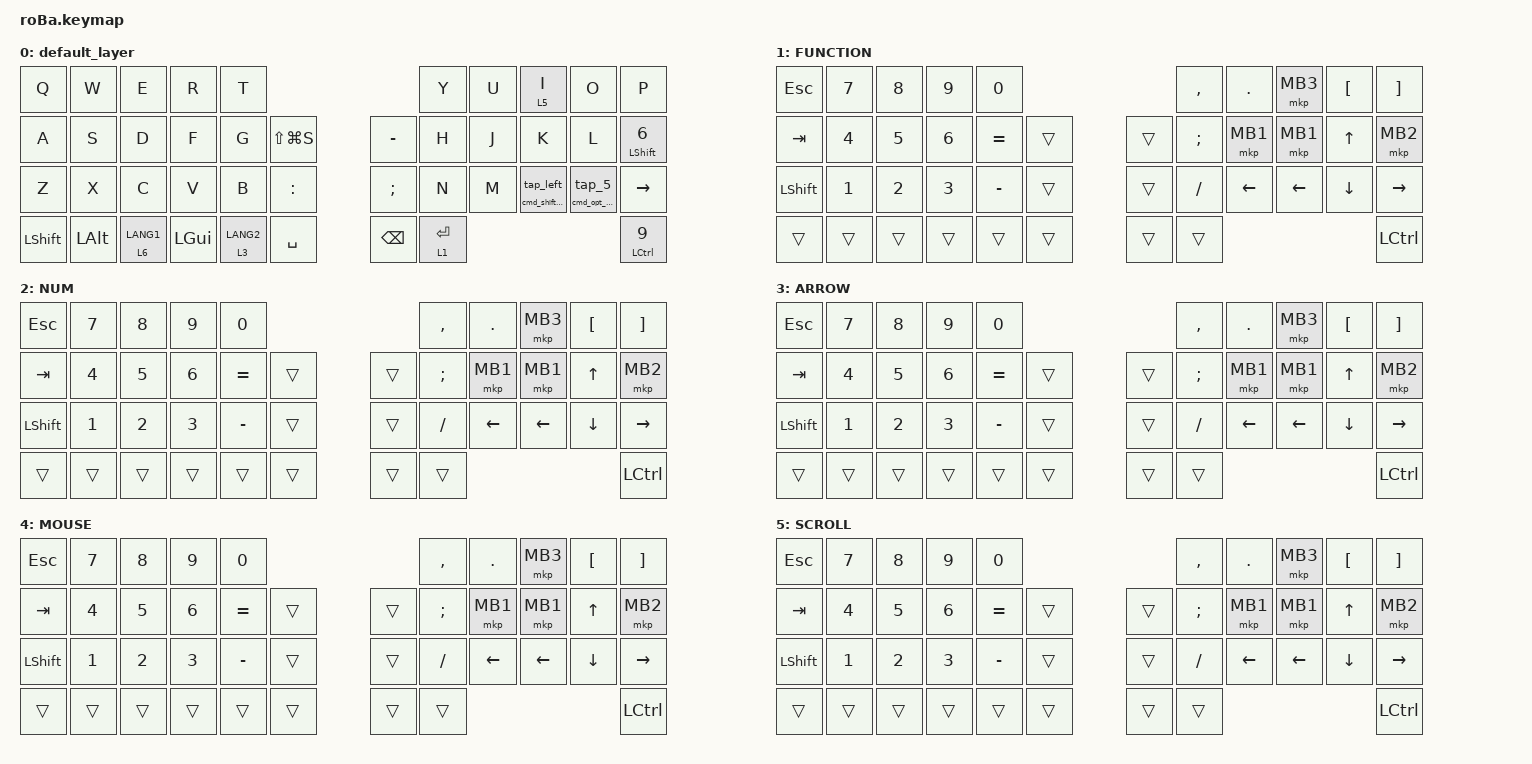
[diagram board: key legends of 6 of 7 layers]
#include <behaviors.dtsi>
#include <dt-bindings/zmk/bt.h>
#include <dt-bindings/zmk/keys.h>
#include <dt-bindings/zmk/pointing.h>

&mt {
    flavor = "balanced";
    quick-tap-ms = <0>;
};

&trackball {
    // automouse-layer = <4>;
    scroll-layers = <5>;
};

 / {
    combos {
        compatible = "zmk,combos";

        tab {
            bindings = <&kp TAB>;
            key-positions = <11 12>;
        };

        shift_tab {
            bindings = <&kp LS(TAB)>;
            key-positions = <12 13>;
        };


        double_quotation {
            bindings = <&kp DOUBLE_QUOTES>;
            key-positions = <20 21>;
        };

        eq {
            bindings = <&kp EQUAL>;
            key-positions = <24 25>;
        };
    };

  macros {
        to_layer_0: to_layer_0 {
            compatible = "zmk,behavior-macro-one-param";
            #binding-cells = <1>;
            bindings = <&to 0 &macro_param_1to1 &kp MACRO_PLACEHOLDER>;
            label = "TO_LAYER_0";
        };

        /* 次の1打鍵だけ ⌘+Shift を有効化（Sticky） */
        cmd_shift_latch: cmd_shift_latch {
            compatible = "zmk,behavior-macro";
            label = "CMD_SHIFT_LATCH";
            #binding-cells = <0>;
            bindings = <&sk LGUI>, <&sk LSHIFT>;
        };

        /* 次の1打鍵だけ ⌘+Option を有効化（Sticky） */
        cmd_opt_latch: cmd_opt_latch {
            compatible = "zmk,behavior-macro";
            label = "CMD_OPT_LATCH";
            #binding-cells = <0>;
            bindings = <&sk LGUI>, <&sk LALT>;
        };

        /* タップ用の単発キー（必要なら流用） */
        tap_left: tap_left {
            compatible = "zmk,behavior-macro";
            label = "TAP_LEFT";
            #binding-cells = <0>;
            bindings = <&kp LEFT_ARROW>;
        };

        tap_5: tap_5 {
            compatible = "zmk,behavior-macro";
            label = "TAP_5";
            #binding-cells = <0>;
            bindings = <&kp NUMBER_5>;
        };
    };

      behaviors {
        /* 既存：タップでレイヤー0へ、ホールドで一時的に別レイヤー（使用側で引数を渡す） */
        lt_to_layer_0: lt_to_layer_0 {
            compatible = "zmk,behavior-hold-tap";
            label = "LAYER_TAP_TO_0";
            #binding-cells = <2>;
            tapping-term-ms = <100>;
            bindings = <&mo>, <&to_layer_0>;
        };

        /* ホールド＝⌘+Shift（Sticky）、タップ＝← */
        ht_cmdshift_left: ht_cmdshift_left {
            compatible = "zmk,behavior-hold-tap";
            label = "HT_CMDSHIFT_LEFT";
            #binding-cells = <2>;
            tapping-term-ms = <200>;
            bindings = <&cmd_shift_latch &tap_left>;
        };

        /* ホールド＝⌘+Option（Sticky）、タップ＝5 */
        ht_cmdopt_5: ht_cmdopt_5 {
            compatible = "zmk,behavior-hold-tap";
            label = "HT_CMDOPT_5";
            #binding-cells = <2>;
            tapping-term-ms = <200>;
            bindings = <&cmd_opt_latch &tap_5>;
        };
    };
    keymap {
        compatible = "zmk,keymap";

        default_layer {
            bindings = <
&kp Q             &kp W         &kp E                        &kp R             &kp T                                                                                 &kp Y          &kp U        &lt 5 I                    &kp O                    &kp P
&kp A             &kp S         &kp D                        &kp F             &kp G                             &kp LS(LG(S))                        &kp MINUS      &kp H          &kp J        &kp K                      &kp L                    &mt LEFT_SHIFT NUMBER_6
&kp Z             &kp X         &kp C                        &kp V             &kp B                             &kp COLON                            &kp SEMICOLON  &kp N          &kp M        &ht_cmdshift_left 0 0      &ht_cmdopt_5 0 0         &kp RIGHT_ARROW
&kp LEFT_SHIFT    &kp LEFT_ALT  &lt_to_layer_0 6 LANG1  &kp LEFT_GUI      &lt 3 LANG2    &kp SPACE                                                    &kp BACKSPACE  &lt 1 ENTER                                                                     &mt LCTRL NUMBER_9
            >;

            sensor-bindings = <&inc_dec_kp UP_ARROW DOWN_ARROW>;
        };

        FUNCTION {
            bindings = <
&kp ESCAPE      &kp NUMBER_7  &kp NUMBER_8   &kp NUMBER_9   &kp NUMBER_0                                 &kp COMMA        &kp PERIOD       &mkp MB3            &kp LBKT         &kp RBKT
&kp TAB         &kp NUMBER_4  &kp NUMBER_5   &kp NUMBER_6   &kp EQUAL     &trans              &trans     &kp SEMI         &mkp MB1         &mkp MB1            &kp UP_ARROW     &mkp MB2
&kp LEFT_SHIFT  &kp NUMBER_1  &kp NUMBER_2   &kp NUMBER_3   &kp MINUS     &trans              &trans     &kp SLASH        &kp LEFT_ARROW   &kp LEFT_ARROW      &kp DOWN_ARROW   &kp RIGHT_ARROW
&trans          &trans        &trans         &trans         &trans        &trans                         &trans           &trans                                                &kp LCTRL
            >;
        };

        NUM {
            bindings = <
&kp ESCAPE      &kp NUMBER_7  &kp NUMBER_8   &kp NUMBER_9   &kp NUMBER_0                                 &kp COMMA        &kp PERIOD       &mkp MB3            &kp LBKT         &kp RBKT
&kp TAB         &kp NUMBER_4  &kp NUMBER_5   &kp NUMBER_6   &kp EQUAL     &trans              &trans     &kp SEMI         &mkp MB1         &mkp MB1            &kp UP_ARROW     &mkp MB2
&kp LEFT_SHIFT  &kp NUMBER_1  &kp NUMBER_2   &kp NUMBER_3   &kp MINUS     &trans              &trans     &kp SLASH        &kp LEFT_ARROW   &kp LEFT_ARROW      &kp DOWN_ARROW   &kp RIGHT_ARROW
&trans          &trans        &trans         &trans         &trans        &trans                         &trans           &trans                                                &kp LCTRL
            >;
        };

        ARROW {
            bindings = <
&kp ESCAPE      &kp NUMBER_7  &kp NUMBER_8   &kp NUMBER_9   &kp NUMBER_0                                 &kp COMMA        &kp PERIOD       &mkp MB3            &kp LBKT         &kp RBKT
&kp TAB         &kp NUMBER_4  &kp NUMBER_5   &kp NUMBER_6   &kp EQUAL     &trans              &trans     &kp SEMI         &mkp MB1         &mkp MB1            &kp UP_ARROW     &mkp MB2
&kp LEFT_SHIFT  &kp NUMBER_1  &kp NUMBER_2   &kp NUMBER_3   &kp MINUS     &trans              &trans     &kp SLASH        &kp LEFT_ARROW   &kp LEFT_ARROW      &kp DOWN_ARROW   &kp RIGHT_ARROW
&trans          &trans        &trans         &trans         &trans        &trans                         &trans           &trans                                                &kp LCTRL
            >;

            sensor-bindings = <&inc_dec_kp LC(PAGE_UP) LC(PAGE_DOWN)>;
        };

        MOUSE {
            bindings = <
&kp ESCAPE      &kp NUMBER_7  &kp NUMBER_8   &kp NUMBER_9   &kp NUMBER_0                                 &kp COMMA        &kp PERIOD       &mkp MB3            &kp LBKT         &kp RBKT
&kp TAB         &kp NUMBER_4  &kp NUMBER_5   &kp NUMBER_6   &kp EQUAL     &trans              &trans     &kp SEMI         &mkp MB1         &mkp MB1            &kp UP_ARROW     &mkp MB2
&kp LEFT_SHIFT  &kp NUMBER_1  &kp NUMBER_2   &kp NUMBER_3   &kp MINUS     &trans              &trans     &kp SLASH        &kp LEFT_ARROW   &kp LEFT_ARROW      &kp DOWN_ARROW   &kp RIGHT_ARROW
&trans          &trans        &trans         &trans         &trans        &trans                         &trans           &trans                                                &kp LCTRL
            >;
        };

        SCROLL {
            bindings = <
&kp ESCAPE      &kp NUMBER_7  &kp NUMBER_8   &kp NUMBER_9   &kp NUMBER_0                                 &kp COMMA        &kp PERIOD       &mkp MB3            &kp LBKT         &kp RBKT
&kp TAB         &kp NUMBER_4  &kp NUMBER_5   &kp NUMBER_6   &kp EQUAL     &trans              &trans     &kp SEMI         &mkp MB1         &mkp MB1            &kp UP_ARROW     &mkp MB2
&kp LEFT_SHIFT  &kp NUMBER_1  &kp NUMBER_2   &kp NUMBER_3   &kp MINUS     &trans              &trans     &kp SLASH        &kp LEFT_ARROW   &kp LEFT_ARROW      &kp DOWN_ARROW   &kp RIGHT_ARROW
&trans          &trans        &trans         &trans         &trans        &trans                         &trans           &trans                                                &kp LCTRL
            >;
        };

        layer_6 {
            bindings = <
&kp F1        &kp F2        &kp F3        &kp F4        &kp F5                                             &trans  &trans  &trans  &trans  &bt BT_CLR
&kp F6        &kp F7        &kp F8        &kp F9        &kp F10                                 &trans     &trans  &trans  &trans  &trans  &bt BT_CLR_ALL
&bt BT_SEL 0  &bt BT_SEL 1  &bt BT_SEL 2  &bt BT_SEL 3  &bt BT_SEL 4   &bootloader              &trans     &trans  &trans  &trans  &trans  &trans
&trans        &trans        &trans        &trans        &trans         &trans                              &trans  &trans                  &trans
            >;

            sensor-bindings = <&inc_dec_kp LC(PAGE_UP) LC(PAGE_DOWN)>;
        };
    };
};
